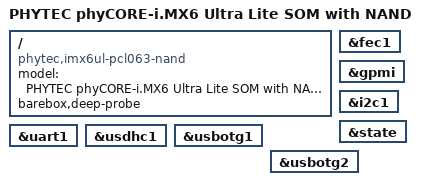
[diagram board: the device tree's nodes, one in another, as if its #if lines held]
// SPDX-License-Identifier: (GPL-2.0-or-later OR MIT)
/*
 * Copyright (C) 2019 PHYTEC Messtechnik GmbH
 * Author: Christian Hemp <c.hemp@phytec.de>
 */

/dts-v1/;
#ifdef CONFIG_BOOTM_FITIMAGE_PUBKEY
#include CONFIG_BOOTM_FITIMAGE_PUBKEY
#endif
#include <arm/nxp/imx/imx6ul.dtsi>
#include "imx6ul-phytec-phycore-som.dtsi"
#include "imx6ul-phytec-state.dtsi"

/ {
	model = "PHYTEC phyCORE-i.MX6 Ultra Lite SOM with NAND";
	compatible = "phytec,imx6ul-pcl063-nand", "fsl,imx6ul";
	barebox,deep-probe;
};

&fec1 {
	status = "okay";
};

&gpmi {
	status = "okay";
};

&i2c1 {
	status = "okay";
};

&state {
	status = "okay";
};

&uart1 {
	status = "okay";
};

&usdhc1 {
	status = "okay";
};

&usbotg1 {
	status = "okay";
};

&usbotg2 {
	status = "okay";
};
